# GD32F527 register map
File version: 1.0
CPU: CM33 r0p1, little endian, MPU, FPU, 4 interrupt priority bits
Registers are 32-bit, read-write, reset 0x0 unless marked. A register's access mark holds for its fields unless they carry their own. Offsets are from the block's base; [hi:lo] are bit positions; {n}, {i} and the like mark numbered series.

## SYSCFG — System and memory architectur
Base 0x40013800
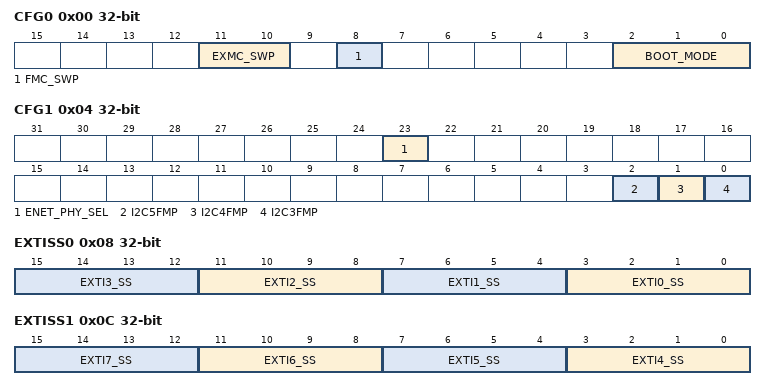
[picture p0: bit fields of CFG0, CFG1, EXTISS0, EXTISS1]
0x00 CFG0 — Configuration register 0
  [11:10] EXMC_SWP — EXMC memory mapping swap
  [8] FMC_SWP — FMC memory mapping swap
  [2:0] BOOT_MODE — These bits select the device accessible at address 0x0000 0000. After reset, they take the initial value from the BOOT0 and BOOT1 pins according to the table.
0x04 CFG1 — Configuration register 1
  [23] ENET_PHY_SEL — Ethernet PHY selection
  [2] I2C5FMP — Enable Fast mode+ on I2C5
  [1] I2C4FMP — Enable Fast mode+ on I2C4
  [0] I2C3FMP — Enable Fast mode+ on I2C3
0x08 EXTISS0 — EXTI sources selection register 0
  [4n+3:4n] EXTI{n}_SS (n=0..3) — EXTI {n} sources selection
0x0C EXTISS1 — EXTI sources selection register 1
  [4n-13:4n-16] EXTI{n}_SS (n=4..7) — EXTI {n} sources selection
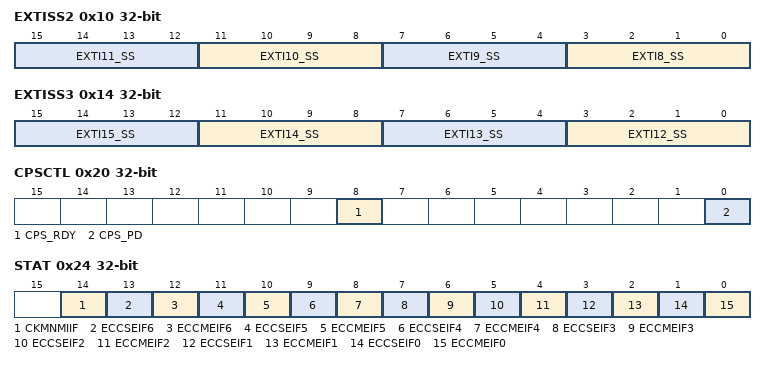
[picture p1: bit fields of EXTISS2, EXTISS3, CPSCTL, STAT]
0x10 EXTISS2 — EXTI sources selection register 2
  [4n-29:4n-32] EXTI{n}_SS (n=8..11) — EXTI {n} sources selection
0x14 EXTISS3 — EXTI sources selection register 3
  [4n-45:4n-48] EXTI{n}_SS (n=12..15) — EXTI {n} sources selection
0x20 CPSCTL access per field — Compensation cell control register
  [8] CPS_RDY ro — Compensation cell ready flag
  [0] CPS_PD rw — Compensation cell power-down
0x24 STAT — System status register 0
  [14] CKMNMIIF — HXTAL clock moniotor NMI interrupt flag
  [13] ECCSEIF6 — Flash single bit correction event flag
  [12] ECCMEIF6 — Flash two bits non-correction event flag
  [11] ECCSEIF5 — BKPSRAM single bit correction event flag
  [10] ECCMEIF5 — Indicates the two bit error
  [9] ECCSEIF4 — TCMSRAM single bit correction event flag
  [8] ECCMEIF4 — TCMSRAM two bits non-correction event flag
  [7] ECCSEIF3 — ADDSRAM single bit correction event flag
  [6] ECCMEIF3 — ADDSRAM two bits non-correction event flag
  [5] ECCSEIF2 — SRAM2 single bit correction event flag
  [4] ECCMEIF2 — SRAM2 two bits non-correction event flag
  [3] ECCSEIF1 — SRAM1 single bit correction event flag
  [2] ECCMEIF1 — SRAM1 two bits non-correction event flag
  [1] ECCSEIF0 — SRAM0 single bit correction event flag
  [0] ECCMEIF0 — SRAM0 two bits non-correction event flag
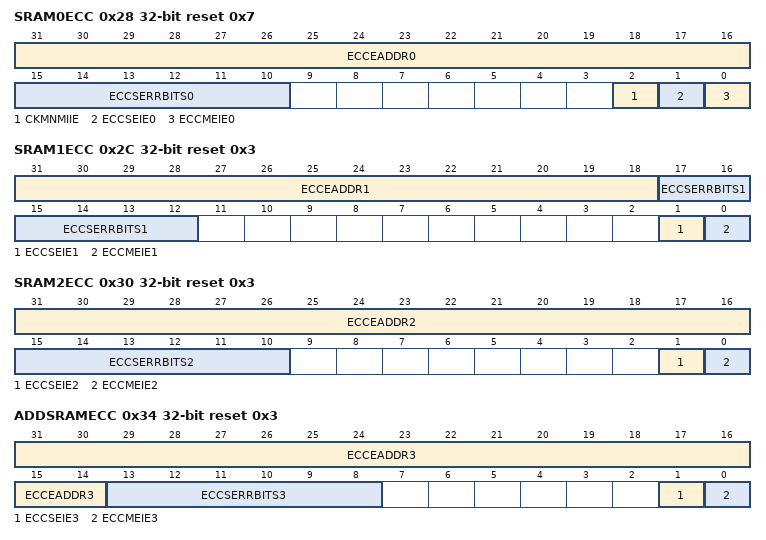
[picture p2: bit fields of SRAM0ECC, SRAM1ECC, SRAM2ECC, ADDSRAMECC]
0x28 SRAM0ECC access per field reset 0x7 — SRAM0 ECC status register
  [31:16] ECCEADDR0 ro — Indicates the last address of ECC event on SRAM0 occurred.
  [15:10] ECCSERRBITS0 ro — Indicates the error bit
  [2] CKMNMIIE rw — HXTAL clock moniotor NMI interrupt enable
  [1] ECCSEIE0 rw — SRAM0 single bit correction interrupt enable
  [0] ECCMEIE0 rw — SRAM0 two bits non-correction interrupt enable
0x2C SRAM1ECC access per field reset 0x3 — SRAM1 ECC status register
  [31:18] ECCEADDR1 ro — Indicates the last address of ECC event on SRAM1 occurred.
  [17:12] ECCSERRBITS1 ro — Indicates the error bit
  [1] ECCSEIE1 rw — SRAM1 single bit correction interrupt enable
  [0] ECCMEIE1 rw — SRAM1 two bits non-correction interrupt enable
0x30 SRAM2ECC access per field reset 0x3 — SRAM2 ECC status register
  [31:16] ECCEADDR2 ro — Indicates the address of ECC event on SRAM2 occurred.
  [15:10] ECCSERRBITS2 ro — Indicates the error bit
  [1] ECCSEIE2 rw — SRAM2 single bit correction interrupt enable
  [0] ECCMEIE2 rw — SRAM2 two bits non-correction interrupt enable
0x34 ADDSRAMECC access per field reset 0x3 — ADDSRAM ECC status register
  [31:14] ECCEADDR3 ro — Indicates the last address of ECC event on ADDSRAM occurred.
  [13:8] ECCSERRBITS3 ro — Indicates the error bit
  [1] ECCSEIE3 rw — ADDSRAM single bit correction interrupt enable
  [0] ECCMEIE3 rw — ADDSRAM two bits non-correction interrupt enable
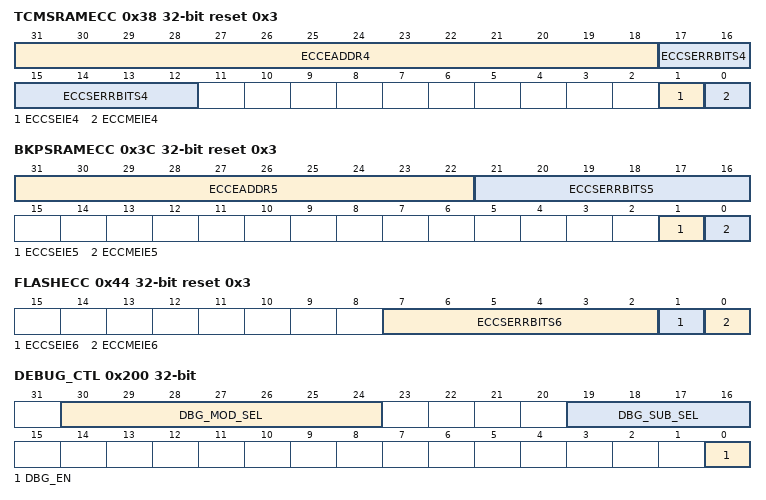
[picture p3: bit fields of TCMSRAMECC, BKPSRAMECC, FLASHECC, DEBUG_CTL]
0x38 TCMSRAMECC access per field reset 0x3
  [31:18] ECCEADDR4 ro — Indicates the last address of ECC event on TCMSRAM occurred.
  [17:12] ECCSERRBITS4 ro — Indicates the error bit
  [1] ECCSEIE4 rw — TCMSRAM single bit correction interrupt enable
  [0] ECCMEIE4 rw — TCMSRAM two bits non-correction interrupt enable
0x3C BKPSRAMECC access per field reset 0x3
  [31:22] ECCEADDR5 ro — Indicates the last address of ECC event on BKPSRAM occurred.
  [21:16] ECCSERRBITS5 ro — Indicates the error bit
  [1] ECCSEIE5 rw — BKPSRAM single bit correction interrupt enable
  [0] ECCMEIE5 rw — BKPSRAM two bits non-correction interrupt enable
0x40 FLASHECC_ADDR ro — FLASH ECC address register
  [31:0] ECCEADDR6 — Indicates the last address of ECC event on FLASH occurred.
0x44 FLASHECC access per field reset 0x3
  [7:2] ECCSERRBITS6 ro — Indicates the error bit
  [1] ECCSEIE6 rw — FLASH single bit correction interrupt enable
  [0] ECCMEIE6 rw — FLASH two bits non-correction interrupt enable
0x200 DEBUG_CTL — DEBUG control register
  [30:24] DBG_MOD_SEL — Debug module selection
  [19:16] DBG_SUB_SEL — Debug subset selection
  [0] DBG_EN — Debug enable
0x300 USER_CFG ro — User configuration register
  [31:24] ANA_VERSION — Analog version information
